# MKE15Z7 register map
Vendor: Freescale Semiconductor, Inc.; Series: Kinetis_E; File version: 1.6
CPU: CM0PLUS r0p0, little endian, no MPU, no FPU, VTOR, 2 interrupt priority bits
Registers are 32-bit, read-write, reset 0x0 unless marked. A register's access mark holds for its fields unless they carry their own. Offsets are from the block's base; [hi:lo] are bit positions; {n}, {i} and the like mark numbered series; 'fields as' and 'values as' point back to an identical list.

## TRGMUX1 — Trigger MUX Control
Base 0x40063000
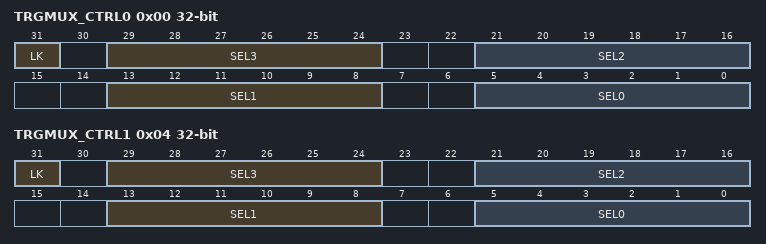
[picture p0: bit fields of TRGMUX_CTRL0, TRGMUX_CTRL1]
0x00 TRGMUX_CTRL0 — TRGMUX Register
  [31] LK ro — Enable
    0=Register can be written; 1=Register cannot be written until the next system Reset
  [8n+5:8n] SEL{n} (n=0..3) — Trigger MUX Input {n} Source Select
0x04 TRGMUX_CTRL1 — TRGMUX Register
  fields as TRGMUX_CTRL0

## PCC
Base 0x40065000
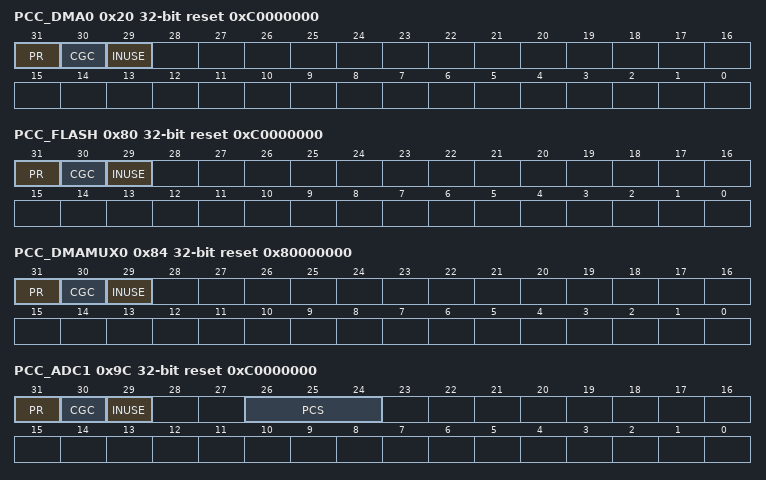
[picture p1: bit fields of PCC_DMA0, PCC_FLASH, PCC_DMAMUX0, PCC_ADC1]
0x20 PCC_DMA0 reset 0xC0000000 — PCC Register
  [31] PR ro — Enable
    0=Peripheral is not present; 1=Peripheral is present
  [30] CGC — Clock Control
    0=Clock disabled; 1=Clock enabled
  [29] INUSE ro — Clock Gate Control
    0=Peripheral is not being used; 1=Peripheral is being used. Software cannot modify the existing clocking configuration.
0x80 PCC_FLASH reset 0xC0000000 — PCC Register
  fields as PCC_DMA0
0x84 PCC_DMAMUX0 reset 0x80000000 — PCC Register
  fields as PCC_DMA0
0x9C PCC_ADC1 reset 0xC0000000 — PCC Register
  [31] PR ro — Enable
    0=Peripheral is not present; 1=Peripheral is present
  [30] CGC — Clock Control
    0=Clock disabled; 1=Clock enabled
  [29] INUSE ro — Clock Gate Control
    values as PCC_DMA0.INUSE
  [26:24] PCS — Peripheral Clock Source Select
    0=Clock is off (or test clock is enabled); 1=OSCCLK - System Oscillator Bus Clock(scg_sosc_slow_clk); 2=SCGIRCLK - Slow IRC Clock(scg_sirc_slow_clk), (maximum is 8MHz); 3=SCGFIRCLK - Fast IRC Clock(scg_firc_slow_clk), (maximum is 48MHz); 6=SCGPCLK System PLL clock(scg_spll_slow_clk)
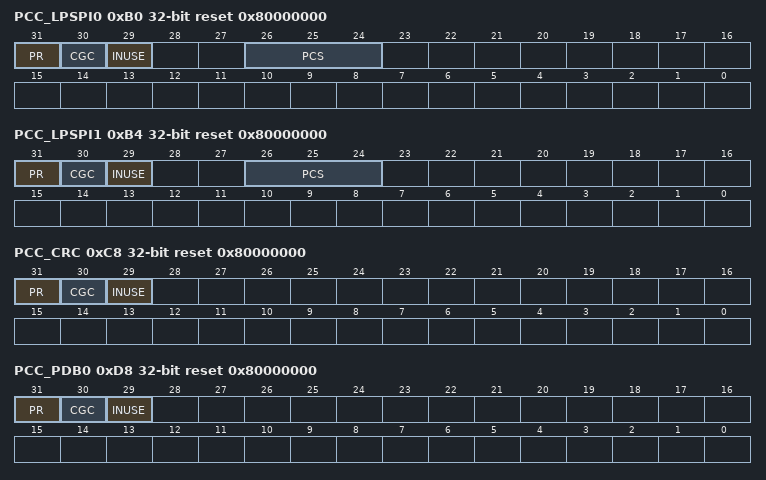
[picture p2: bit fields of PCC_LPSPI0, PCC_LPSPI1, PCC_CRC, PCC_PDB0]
0xB0 PCC_LPSPI0 reset 0x80000000 — PCC Register
  fields as PCC_ADC1
0xB4 PCC_LPSPI1 reset 0x80000000 — PCC Register
  fields as PCC_ADC1
0xC8 PCC_CRC reset 0x80000000 — PCC Register
  fields as PCC_DMA0
0xD8 PCC_PDB0 reset 0x80000000 — PCC Register
  fields as PCC_DMA0
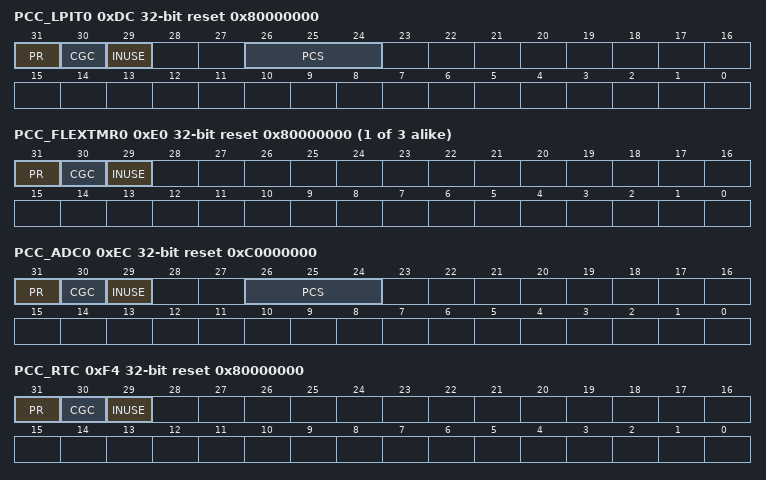
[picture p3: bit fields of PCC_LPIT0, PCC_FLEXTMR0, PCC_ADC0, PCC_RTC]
0xDC PCC_LPIT0 reset 0x80000000 — PCC Register
  fields as PCC_ADC1
{0xE0+4i} PCC_FLEXTMR{i} reset 0x80000000 (i=0..2) — PCC Register
  fields as PCC_DMA0
0xEC PCC_ADC0 reset 0xC0000000 — PCC Register
  fields as PCC_ADC1
0xF4 PCC_RTC reset 0x80000000 — PCC Register
  fields as PCC_DMA0
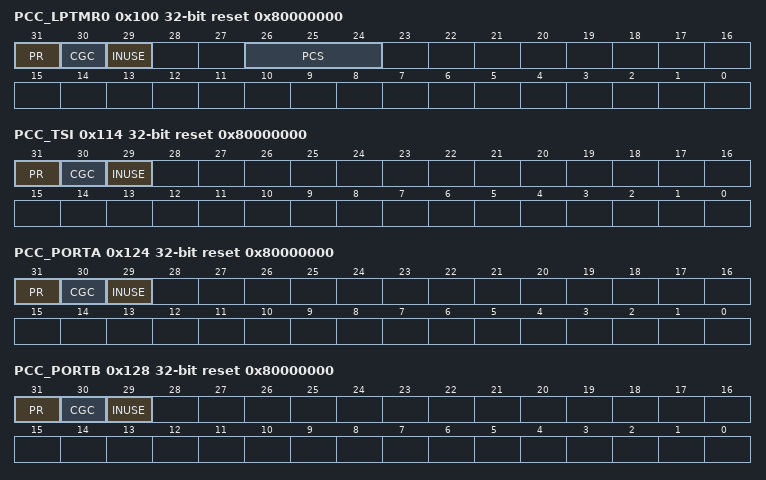
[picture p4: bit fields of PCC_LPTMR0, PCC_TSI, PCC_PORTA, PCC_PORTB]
0x100 PCC_LPTMR0 reset 0x80000000 — PCC Register
  fields as PCC_ADC1
0x114 PCC_TSI reset 0x80000000 — PCC Register
  fields as PCC_DMA0
0x124 PCC_PORTA reset 0x80000000 — PCC Register
  fields as PCC_DMA0
0x128 PCC_PORTB reset 0x80000000 — PCC Register
  fields as PCC_DMA0
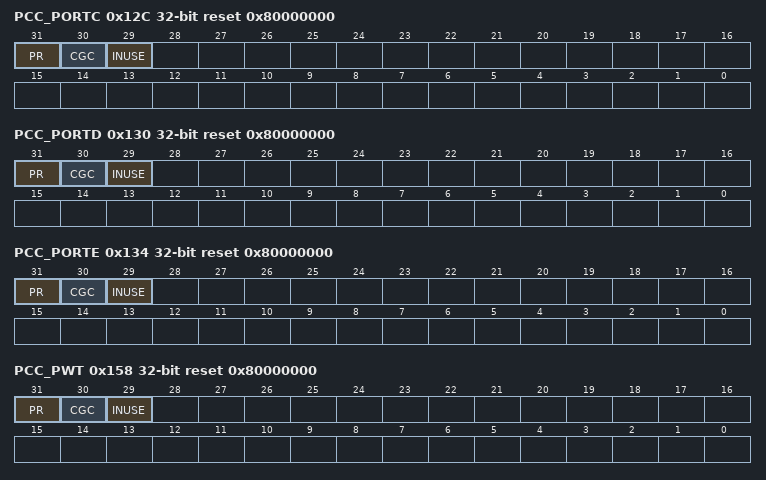
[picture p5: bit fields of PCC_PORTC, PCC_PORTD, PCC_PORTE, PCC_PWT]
0x12C PCC_PORTC reset 0x80000000 — PCC Register
  fields as PCC_DMA0
0x130 PCC_PORTD reset 0x80000000 — PCC Register
  fields as PCC_DMA0
0x134 PCC_PORTE reset 0x80000000 — PCC Register
  fields as PCC_DMA0
0x158 PCC_PWT reset 0x80000000 — PCC Register
  fields as PCC_DMA0
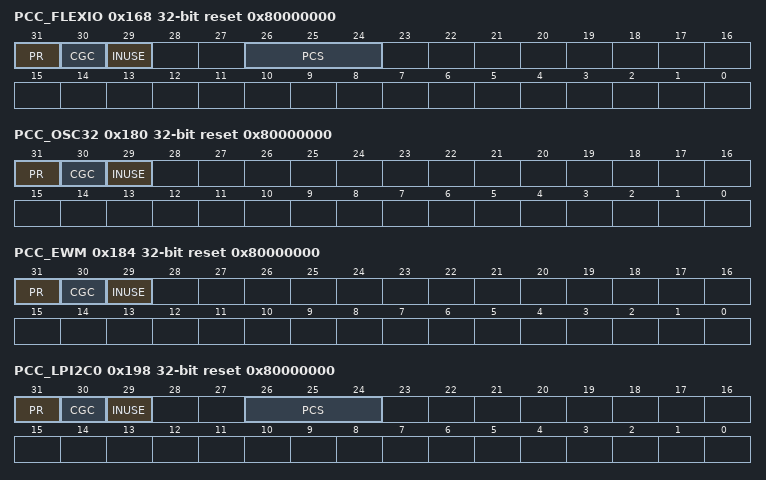
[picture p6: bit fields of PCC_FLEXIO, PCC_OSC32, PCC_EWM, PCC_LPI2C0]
0x168 PCC_FLEXIO reset 0x80000000 — PCC Register
  fields as PCC_ADC1
0x180 PCC_OSC32 reset 0x80000000 — PCC Register
  fields as PCC_DMA0
0x184 PCC_EWM reset 0x80000000 — PCC Register
  fields as PCC_DMA0
0x198 PCC_LPI2C0 reset 0x80000000 — PCC Register
  fields as PCC_ADC1
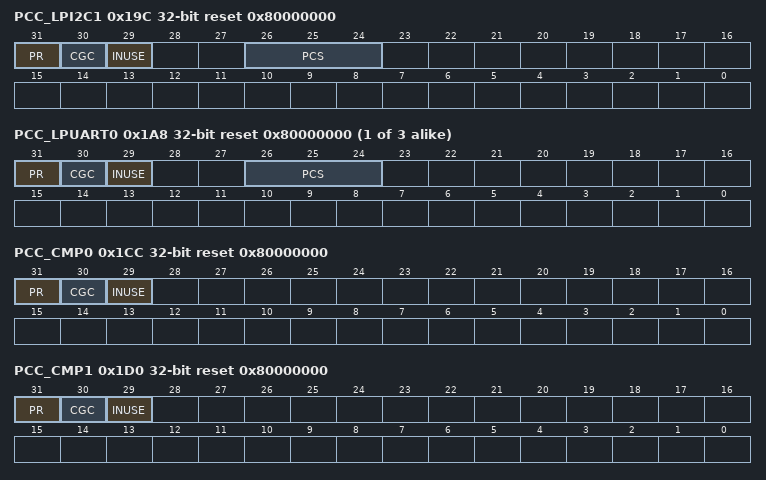
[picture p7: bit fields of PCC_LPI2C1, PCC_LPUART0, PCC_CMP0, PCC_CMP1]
0x19C PCC_LPI2C1 reset 0x80000000 — PCC Register
  fields as PCC_ADC1
{0x1A8+4i} PCC_LPUART{i} reset 0x80000000 (i=0..2) — PCC Register
  fields as PCC_ADC1
0x1CC PCC_CMP0 reset 0x80000000 — PCC Register
  fields as PCC_DMA0
0x1D0 PCC_CMP1 reset 0x80000000 — PCC Register
  fields as PCC_DMA0

## PMC
Base 0x4007D000; register names take the prefix PMC_
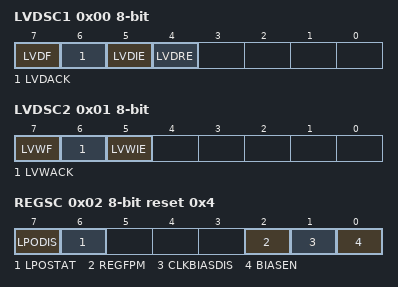
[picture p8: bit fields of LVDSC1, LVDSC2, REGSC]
0x00 LVDSC1 8-bit — Low Voltage Detect Status and Control 1 Register
  [7] LVDF ro — Low Voltage Detect Flag
    0=Low-voltage event not detected; 1=Low-voltage event detected
  [6] LVDACK wo — Low Voltage Detect Acknowledge
  [5] LVDIE — Low Voltage Detect Interrupt Enable
    0=Hardware interrupt disabled (use polling); 1=Request a hardware interrupt when LVDF = 1
  [4] LVDRE — Low Voltage Detect Reset Enable
    0=No system resets on low voltage detect events; 1=If the supply voltage falls below VLVD, a system reset will be generated
0x01 LVDSC2 8-bit — Low Voltage Detect Status and Control 2 Register
  [7] LVWF ro — Low-Voltage Warning Flag
    0=Low-voltage warning event not detected; 1=Low-voltage warning event detected
  [6] LVWACK wo — Low-Voltage Warning Acknowledge
  [5] LVWIE — Low-Voltage Warning Interrupt Enable
    0=Hardware interrupt disabled (use polling); 1=Request a hardware interrupt when LVWF=1
0x02 REGSC 8-bit reset 0x4 — Regulator Status and Control Register
  [7] LPODIS — LPO Disable Bit
    0=Low power oscillator enabled; 1=Low power oscillator disabled
  [6] LPOSTAT ro — LPO Status Bit
    0=Low power oscillator in low phase; 1=Low power oscillator in high phase
  [2] REGFPM ro — Regulator in Full Performance Mode Status Bit
    0=Regulator is in low power mode or transition to/from; 1=Regulator is in full performance mode
  [1] CLKBIASDIS — Clock Bias Disable Bit
    0=No effect; 1=In STOP or VLPS mode the bias currents and reference voltages for the following clock modules are disabled: SIRC, FIRC, PLL. (if available on device)
  [0] BIASEN — Bias Enable Bit
    0=Biasing disabled, core logic can run in full performance; 1=Biasing enabled, core logic is slower and there are restrictions in allowed system clock speed (see Data Sheet for details)
0x04 LPOTRIM 8-bit — Low Power Oscillator Trim Register
  [4:0] LPOTRIM — LPO trimming bits
